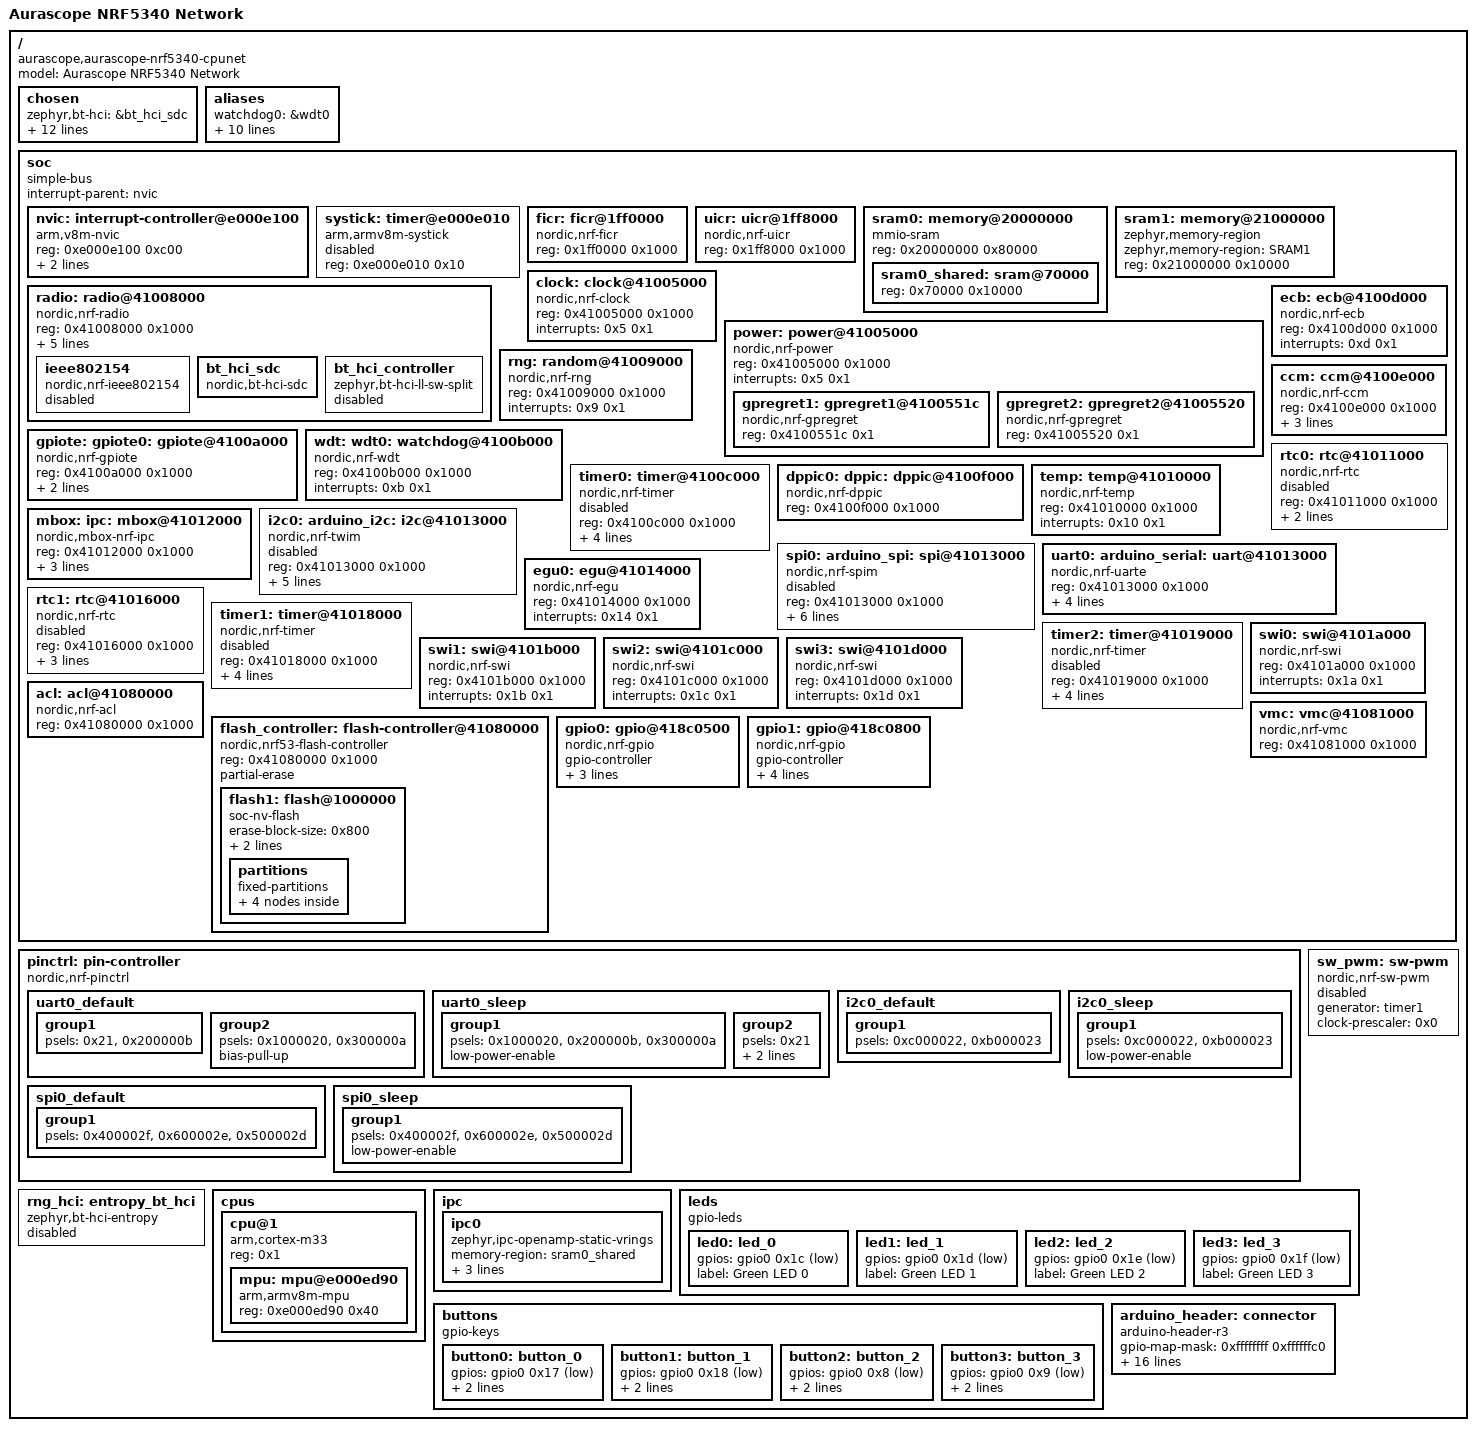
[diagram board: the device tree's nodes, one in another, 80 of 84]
/dts-v1/;

/* node '/' defined in zephyr/dts/common/skeleton.dtsi:9 */
/ {
	#address-cells = < 0x1 >;                          /* in zephyr/dts/common/skeleton.dtsi:10 */
	#size-cells = < 0x1 >;                             /* in zephyr/dts/common/skeleton.dtsi:11 */
	model = "Aurascope NRF5340 Network";               /* in nrf/boards/aurascope/aurascope/aurascope_nrf5340_cpunet.dts:12 */
	compatible = "aurascope,aurascope-nrf5340-cpunet"; /* in nrf/boards/aurascope/aurascope/aurascope_nrf5340_cpunet.dts:13 */

	/* node '/chosen' defined in zephyr/dts/common/skeleton.dtsi:13 */
	chosen {
		zephyr,bt-hci = &bt_hci_sdc;                 /* in zephyr/dts/arm/nordic/nrf5340_cpunet.dtsi:12 */
		zephyr,entropy = &rng;                       /* in zephyr/dts/arm/nordic/nrf5340_cpunet.dtsi:13 */
		zephyr,flash-controller = &flash_controller; /* in zephyr/dts/arm/nordic/nrf5340_cpunet.dtsi:14 */
		zephyr,console = &uart0;                     /* in nrf/boards/aurascope/aurascope/aurascope_nrf5340_cpunet.dts:16 */
		zephyr,shell-uart = &uart0;                  /* in nrf/boards/aurascope/aurascope/aurascope_nrf5340_cpunet.dts:17 */
		zephyr,uart-mcumgr = &uart0;                 /* in nrf/boards/aurascope/aurascope/aurascope_nrf5340_cpunet.dts:18 */
		zephyr,bt-mon-uart = &uart0;                 /* in nrf/boards/aurascope/aurascope/aurascope_nrf5340_cpunet.dts:19 */
		zephyr,bt-c2h-uart = &uart0;                 /* in nrf/boards/aurascope/aurascope/aurascope_nrf5340_cpunet.dts:20 */
		zephyr,bt-hci-ipc = &ipc0;                   /* in nrf/boards/aurascope/aurascope/aurascope_nrf5340_cpunet.dts:21 */
		zephyr,sram = &sram1;                        /* in nrf/boards/aurascope/aurascope/aurascope_nrf5340_cpunet.dts:22 */
		zephyr,flash = &flash1;                      /* in nrf/boards/aurascope/aurascope/aurascope_nrf5340_cpunet.dts:23 */
		zephyr,code-partition = &slot0_partition;    /* in nrf/boards/aurascope/aurascope/aurascope_nrf5340_cpunet.dts:24 */
		zephyr,ipc_shm = &sram0_shared;              /* in zephyr/dts/vendor/nordic/nrf5340_shared_sram_partition.dtsi:22 */
	};

	/* node '/aliases' defined in zephyr/dts/common/skeleton.dtsi:15 */
	aliases {
		watchdog0 = &wdt0;          /* in nrf/boards/aurascope/aurascope/aurascope_nrf5340_cpunet.dts:29 */
		led0 = &led0;               /* in nrf/boards/aurascope/aurascope/aurascope_nrf5340_shared.dtsi:93 */
		led1 = &led1;               /* in nrf/boards/aurascope/aurascope/aurascope_nrf5340_shared.dtsi:94 */
		led2 = &led2;               /* in nrf/boards/aurascope/aurascope/aurascope_nrf5340_shared.dtsi:95 */
		led3 = &led3;               /* in nrf/boards/aurascope/aurascope/aurascope_nrf5340_shared.dtsi:96 */
		sw0 = &button0;             /* in nrf/boards/aurascope/aurascope/aurascope_nrf5340_shared.dtsi:97 */
		sw1 = &button1;             /* in nrf/boards/aurascope/aurascope/aurascope_nrf5340_shared.dtsi:98 */
		sw2 = &button2;             /* in nrf/boards/aurascope/aurascope/aurascope_nrf5340_shared.dtsi:99 */
		sw3 = &button3;             /* in nrf/boards/aurascope/aurascope/aurascope_nrf5340_shared.dtsi:100 */
		mcuboot-button0 = &button0; /* in nrf/boards/aurascope/aurascope/aurascope_nrf5340_shared.dtsi:101 */
		mcuboot-led0 = &led0;       /* in nrf/boards/aurascope/aurascope/aurascope_nrf5340_shared.dtsi:102 */
	};

	/* node '/soc' defined in zephyr/dts/arm/armv8-m.dtsi:6 */
	soc {
		#address-cells = < 0x1 >;     /* in zephyr/dts/arm/armv8-m.dtsi:7 */
		#size-cells = < 0x1 >;        /* in zephyr/dts/arm/armv8-m.dtsi:8 */
		interrupt-parent = < &nvic >; /* in zephyr/dts/arm/armv8-m.dtsi:10 */
		ranges;                       /* in zephyr/dts/arm/armv8-m.dtsi:11 */
		compatible = "simple-bus";    /* in zephyr/dts/arm/nordic/nrf5340_cpunet_qkaa.dtsi:27 */

		/* node '/soc/interrupt-controller@e000e100' defined in zephyr/dts/arm/armv8-m.dtsi:13 */
		nvic: interrupt-controller@e000e100 {
			#address-cells = < 0x1 >;            /* in zephyr/dts/arm/armv8-m.dtsi:14 */
			compatible = "arm,v8m-nvic";         /* in zephyr/dts/arm/armv8-m.dtsi:15 */
			reg = < 0xe000e100 0xc00 >;          /* in zephyr/dts/arm/armv8-m.dtsi:16 */
			interrupt-controller;                /* in zephyr/dts/arm/armv8-m.dtsi:17 */
			#interrupt-cells = < 0x2 >;          /* in zephyr/dts/arm/armv8-m.dtsi:18 */
			arm,num-irq-priority-bits = < 0x3 >; /* in zephyr/dts/arm/nordic/nrf5340_cpunet.dtsi:368 */
			phandle = < 0x1 >;                   /* in zephyr/dts/arm/armv8-m.dtsi:10 */
		};

		/* node '/soc/timer@e000e010' defined in zephyr/dts/arm/armv8-m.dtsi:21 */
		systick: timer@e000e010 {
			compatible = "arm,armv8m-systick"; /* in zephyr/dts/arm/armv8-m.dtsi:22 */
			reg = < 0xe000e010 0x10 >;         /* in zephyr/dts/arm/armv8-m.dtsi:23 */
			status = "disabled";               /* in zephyr/dts/arm/nordic/nrf5340_cpunet.dtsi:373 */
		};

		/* node '/soc/ficr@1ff0000' defined in zephyr/dts/arm/nordic/nrf5340_cpunet.dtsi:36 */
		ficr: ficr@1ff0000 {
			compatible = "nordic,nrf-ficr"; /* in zephyr/dts/arm/nordic/nrf5340_cpunet.dtsi:37 */
			reg = < 0x1ff0000 0x1000 >;     /* in zephyr/dts/arm/nordic/nrf5340_cpunet.dtsi:38 */
			#nordic,ficr-cells = < 0x1 >;   /* in zephyr/dts/arm/nordic/nrf5340_cpunet.dtsi:39 */
			status = "okay";                /* in zephyr/dts/arm/nordic/nrf5340_cpunet.dtsi:40 */
		};

		/* node '/soc/uicr@1ff8000' defined in zephyr/dts/arm/nordic/nrf5340_cpunet.dtsi:43 */
		uicr: uicr@1ff8000 {
			compatible = "nordic,nrf-uicr"; /* in zephyr/dts/arm/nordic/nrf5340_cpunet.dtsi:44 */
			reg = < 0x1ff8000 0x1000 >;     /* in zephyr/dts/arm/nordic/nrf5340_cpunet.dtsi:45 */
			status = "okay";                /* in zephyr/dts/arm/nordic/nrf5340_cpunet.dtsi:46 */
		};

		/* node '/soc/memory@20000000' defined in zephyr/dts/arm/nordic/nrf5340_cpunet.dtsi:49 */
		sram0: memory@20000000 {
			compatible = "mmio-sram";            /* in zephyr/dts/arm/nordic/nrf5340_cpunet.dtsi:50 */
			#address-cells = < 0x1 >;            /* in zephyr/dts/arm/nordic/nrf5340_cpunet.dtsi:51 */
			#size-cells = < 0x1 >;               /* in zephyr/dts/arm/nordic/nrf5340_cpunet.dtsi:52 */
			reg = < 0x20000000 0x80000 >;        /* in zephyr/dts/arm/nordic/nrf5340_cpunet_qkaa.dtsi:16 */
			ranges = < 0x0 0x20000000 0x80000 >; /* in zephyr/dts/arm/nordic/nrf5340_cpunet_qkaa.dtsi:17 */

			/* node '/soc/memory@20000000/sram@70000' defined in zephyr/dts/vendor/nordic/nrf5340_shared_sram_partition.dtsi:27 */
			sram0_shared: sram@70000 {
				reg = < 0x70000 0x10000 >; /* in zephyr/dts/vendor/nordic/nrf5340_shared_sram_partition.dtsi:29 */
				phandle = < 0xb >;         /* in zephyr/dts/arm/nordic/nrf5340_cpunet.dtsi:358 */
			};
		};

		/* node '/soc/memory@21000000' defined in zephyr/dts/arm/nordic/nrf5340_cpunet.dtsi:55 */
		sram1: memory@21000000 {
			compatible = "zephyr,memory-region",
			             "mmio-sram";            /* in zephyr/dts/arm/nordic/nrf5340_cpunet.dtsi:56 */
			zephyr,memory-region = "SRAM1";      /* in zephyr/dts/arm/nordic/nrf5340_cpunet.dtsi:57 */
			#address-cells = < 0x1 >;            /* in zephyr/dts/arm/nordic/nrf5340_cpunet.dtsi:58 */
			#size-cells = < 0x1 >;               /* in zephyr/dts/arm/nordic/nrf5340_cpunet.dtsi:59 */
			reg = < 0x21000000 0x10000 >;        /* in zephyr/dts/arm/nordic/nrf5340_cpunet_qkaa.dtsi:21 */
			ranges = < 0x0 0x21000000 0x10000 >; /* in zephyr/dts/arm/nordic/nrf5340_cpunet_qkaa.dtsi:22 */
		};

		/* node '/soc/clock@41005000' defined in zephyr/dts/arm/nordic/nrf5340_cpunet.dtsi:62 */
		clock: clock@41005000 {
			compatible = "nordic,nrf-clock"; /* in zephyr/dts/arm/nordic/nrf5340_cpunet.dtsi:63 */
			reg = < 0x41005000 0x1000 >;     /* in zephyr/dts/arm/nordic/nrf5340_cpunet.dtsi:64 */
			interrupts = < 0x5 0x1 >;        /* in zephyr/dts/arm/nordic/nrf5340_cpunet.dtsi:65 */
			status = "okay";                 /* in zephyr/dts/arm/nordic/nrf5340_cpunet.dtsi:66 */
		};

		/* node '/soc/power@41005000' defined in zephyr/dts/arm/nordic/nrf5340_cpunet.dtsi:69 */
		power: power@41005000 {
			compatible = "nordic,nrf-power"; /* in zephyr/dts/arm/nordic/nrf5340_cpunet.dtsi:70 */
			reg = < 0x41005000 0x1000 >;     /* in zephyr/dts/arm/nordic/nrf5340_cpunet.dtsi:71 */
			interrupts = < 0x5 0x1 >;        /* in zephyr/dts/arm/nordic/nrf5340_cpunet.dtsi:72 */
			status = "okay";                 /* in zephyr/dts/arm/nordic/nrf5340_cpunet.dtsi:73 */
			#address-cells = < 0x1 >;        /* in zephyr/dts/arm/nordic/nrf5340_cpunet.dtsi:74 */
			#size-cells = < 0x1 >;           /* in zephyr/dts/arm/nordic/nrf5340_cpunet.dtsi:75 */

			/* node '/soc/power@41005000/gpregret1@4100551c' defined in zephyr/dts/arm/nordic/nrf5340_cpunet.dtsi:77 */
			gpregret1: gpregret1@4100551c {
				#address-cells = < 0x1 >;           /* in zephyr/dts/arm/nordic/nrf5340_cpunet.dtsi:78 */
				#size-cells = < 0x1 >;              /* in zephyr/dts/arm/nordic/nrf5340_cpunet.dtsi:79 */
				compatible = "nordic,nrf-gpregret"; /* in zephyr/dts/arm/nordic/nrf5340_cpunet.dtsi:80 */
				reg = < 0x4100551c 0x1 >;           /* in zephyr/dts/arm/nordic/nrf5340_cpunet.dtsi:81 */
				status = "okay";                    /* in zephyr/dts/arm/nordic/nrf5340_cpunet.dtsi:82 */
			};

			/* node '/soc/power@41005000/gpregret2@41005520' defined in zephyr/dts/arm/nordic/nrf5340_cpunet.dtsi:85 */
			gpregret2: gpregret2@41005520 {
				#address-cells = < 0x1 >;           /* in zephyr/dts/arm/nordic/nrf5340_cpunet.dtsi:86 */
				#size-cells = < 0x1 >;              /* in zephyr/dts/arm/nordic/nrf5340_cpunet.dtsi:87 */
				compatible = "nordic,nrf-gpregret"; /* in zephyr/dts/arm/nordic/nrf5340_cpunet.dtsi:88 */
				reg = < 0x41005520 0x1 >;           /* in zephyr/dts/arm/nordic/nrf5340_cpunet.dtsi:89 */
				status = "okay";                    /* in zephyr/dts/arm/nordic/nrf5340_cpunet.dtsi:90 */
			};
		};

		/* node '/soc/radio@41008000' defined in zephyr/dts/arm/nordic/nrf5340_cpunet.dtsi:94 */
		radio: radio@41008000 {
			compatible = "nordic,nrf-radio"; /* in zephyr/dts/arm/nordic/nrf5340_cpunet.dtsi:95 */
			reg = < 0x41008000 0x1000 >;     /* in zephyr/dts/arm/nordic/nrf5340_cpunet.dtsi:96 */
			interrupts = < 0x8 0x1 >;        /* in zephyr/dts/arm/nordic/nrf5340_cpunet.dtsi:97 */
			status = "okay";                 /* in zephyr/dts/arm/nordic/nrf5340_cpunet.dtsi:98 */
			dfe-supported;                   /* in zephyr/dts/arm/nordic/nrf5340_cpunet.dtsi:99 */
			ieee802154-supported;            /* in zephyr/dts/arm/nordic/nrf5340_cpunet.dtsi:100 */
			ble-2mbps-supported;             /* in zephyr/dts/arm/nordic/nrf5340_cpunet.dtsi:101 */
			ble-coded-phy-supported;         /* in zephyr/dts/arm/nordic/nrf5340_cpunet.dtsi:102 */

			/* node '/soc/radio@41008000/ieee802154' defined in zephyr/dts/arm/nordic/nrf5340_cpunet.dtsi:104 */
			ieee802154: ieee802154 {
				compatible = "nordic,nrf-ieee802154"; /* in zephyr/dts/arm/nordic/nrf5340_cpunet.dtsi:105 */
				status = "disabled";                  /* in zephyr/dts/arm/nordic/nrf5340_cpunet.dtsi:106 */
			};

			/* node '/soc/radio@41008000/bt_hci_sdc' defined in zephyr/dts/arm/nordic/nrf5340_cpunet.dtsi:109 */
			bt_hci_sdc: bt_hci_sdc {
				compatible = "nordic,bt-hci-sdc"; /* in zephyr/dts/arm/nordic/nrf5340_cpunet.dtsi:110 */
				status = "okay";                  /* in zephyr/dts/arm/nordic/nrf5340_cpunet.dtsi:111 */
			};

			/* node '/soc/radio@41008000/bt_hci_controller' defined in zephyr/dts/arm/nordic/nrf5340_cpunet.dtsi:113 */
			bt_hci_controller: bt_hci_controller {
				compatible = "zephyr,bt-hci-ll-sw-split"; /* in zephyr/dts/arm/nordic/nrf5340_cpunet.dtsi:114 */
				status = "disabled";                      /* in zephyr/dts/arm/nordic/nrf5340_cpunet.dtsi:115 */
			};
		};

		/* node '/soc/random@41009000' defined in zephyr/dts/arm/nordic/nrf5340_cpunet.dtsi:119 */
		rng: random@41009000 {
			compatible = "nordic,nrf-rng"; /* in zephyr/dts/arm/nordic/nrf5340_cpunet.dtsi:120 */
			reg = < 0x41009000 0x1000 >;   /* in zephyr/dts/arm/nordic/nrf5340_cpunet.dtsi:121 */
			interrupts = < 0x9 0x1 >;      /* in zephyr/dts/arm/nordic/nrf5340_cpunet.dtsi:122 */
			status = "okay";               /* in zephyr/dts/arm/nordic/nrf5340_cpunet.dtsi:123 */
		};

		/* node '/soc/gpiote@4100a000' defined in zephyr/dts/arm/nordic/nrf5340_cpunet.dtsi:126 */
		gpiote: gpiote0: gpiote@4100a000 {
			compatible = "nordic,nrf-gpiote"; /* in zephyr/dts/arm/nordic/nrf5340_cpunet.dtsi:127 */
			reg = < 0x4100a000 0x1000 >;      /* in zephyr/dts/arm/nordic/nrf5340_cpunet.dtsi:128 */
			interrupts = < 0xa 0x5 >;         /* in zephyr/dts/arm/nordic/nrf5340_cpunet.dtsi:129 */
			instance = < 0x0 >;               /* in zephyr/dts/arm/nordic/nrf5340_cpunet.dtsi:131 */
			status = "okay";                  /* in nrf/boards/aurascope/aurascope/aurascope_nrf5340_cpunet.dts:55 */
			phandle = < 0x9 >;                /* in zephyr/dts/arm/nordic/nrf5340_cpunet.dtsi:339 */
		};

		/* node '/soc/watchdog@4100b000' defined in zephyr/dts/arm/nordic/nrf5340_cpunet.dtsi:134 */
		wdt: wdt0: watchdog@4100b000 {
			compatible = "nordic,nrf-wdt"; /* in zephyr/dts/arm/nordic/nrf5340_cpunet.dtsi:135 */
			reg = < 0x4100b000 0x1000 >;   /* in zephyr/dts/arm/nordic/nrf5340_cpunet.dtsi:136 */
			interrupts = < 0xb 0x1 >;      /* in zephyr/dts/arm/nordic/nrf5340_cpunet.dtsi:137 */
			status = "okay";               /* in zephyr/dts/arm/nordic/nrf5340_cpunet.dtsi:138 */
		};

		/* node '/soc/timer@4100c000' defined in zephyr/dts/arm/nordic/nrf5340_cpunet.dtsi:141 */
		timer0: timer@4100c000 {
			compatible = "nordic,nrf-timer"; /* in zephyr/dts/arm/nordic/nrf5340_cpunet.dtsi:142 */
			status = "disabled";             /* in zephyr/dts/arm/nordic/nrf5340_cpunet.dtsi:143 */
			reg = < 0x4100c000 0x1000 >;     /* in zephyr/dts/arm/nordic/nrf5340_cpunet.dtsi:144 */
			cc-num = < 0x8 >;                /* in zephyr/dts/arm/nordic/nrf5340_cpunet.dtsi:145 */
			max-bit-width = < 0x20 >;        /* in zephyr/dts/arm/nordic/nrf5340_cpunet.dtsi:146 */
			interrupts = < 0xc 0x1 >;        /* in zephyr/dts/arm/nordic/nrf5340_cpunet.dtsi:147 */
			prescaler = < 0x0 >;             /* in zephyr/dts/arm/nordic/nrf5340_cpunet.dtsi:148 */
		};

		/* node '/soc/ecb@4100d000' defined in zephyr/dts/arm/nordic/nrf5340_cpunet.dtsi:151 */
		ecb: ecb@4100d000 {
			compatible = "nordic,nrf-ecb"; /* in zephyr/dts/arm/nordic/nrf5340_cpunet.dtsi:152 */
			reg = < 0x4100d000 0x1000 >;   /* in zephyr/dts/arm/nordic/nrf5340_cpunet.dtsi:153 */
			interrupts = < 0xd 0x1 >;      /* in zephyr/dts/arm/nordic/nrf5340_cpunet.dtsi:154 */
			status = "okay";               /* in zephyr/dts/arm/nordic/nrf5340_cpunet.dtsi:155 */
		};

		/* node '/soc/ccm@4100e000' defined in zephyr/dts/arm/nordic/nrf5340_cpunet.dtsi:158 */
		ccm: ccm@4100e000 {
			compatible = "nordic,nrf-ccm"; /* in zephyr/dts/arm/nordic/nrf5340_cpunet.dtsi:159 */
			reg = < 0x4100e000 0x1000 >;   /* in zephyr/dts/arm/nordic/nrf5340_cpunet.dtsi:160 */
			interrupts = < 0xe 0x1 >;      /* in zephyr/dts/arm/nordic/nrf5340_cpunet.dtsi:161 */
			length-field-length-8-bits;    /* in zephyr/dts/arm/nordic/nrf5340_cpunet.dtsi:162 */
			headermask-supported;          /* in zephyr/dts/arm/nordic/nrf5340_cpunet.dtsi:163 */
			status = "okay";               /* in zephyr/dts/arm/nordic/nrf5340_cpunet.dtsi:164 */
		};

		/* node '/soc/dppic@4100f000' defined in zephyr/dts/arm/nordic/nrf5340_cpunet.dtsi:167 */
		dppic0: dppic: dppic@4100f000 {
			compatible = "nordic,nrf-dppic"; /* in zephyr/dts/arm/nordic/nrf5340_cpunet.dtsi:168 */
			reg = < 0x4100f000 0x1000 >;     /* in zephyr/dts/arm/nordic/nrf5340_cpunet.dtsi:169 */
			status = "okay";                 /* in zephyr/dts/arm/nordic/nrf5340_cpunet.dtsi:170 */
		};

		/* node '/soc/temp@41010000' defined in zephyr/dts/arm/nordic/nrf5340_cpunet.dtsi:173 */
		temp: temp@41010000 {
			compatible = "nordic,nrf-temp"; /* in zephyr/dts/arm/nordic/nrf5340_cpunet.dtsi:174 */
			reg = < 0x41010000 0x1000 >;    /* in zephyr/dts/arm/nordic/nrf5340_cpunet.dtsi:175 */
			interrupts = < 0x10 0x1 >;      /* in zephyr/dts/arm/nordic/nrf5340_cpunet.dtsi:176 */
			status = "okay";                /* in zephyr/dts/arm/nordic/nrf5340_cpunet.dtsi:177 */
		};

		/* node '/soc/rtc@41011000' defined in zephyr/dts/arm/nordic/nrf5340_cpunet.dtsi:180 */
		rtc0: rtc@41011000 {
			compatible = "nordic,nrf-rtc"; /* in zephyr/dts/arm/nordic/nrf5340_cpunet.dtsi:181 */
			reg = < 0x41011000 0x1000 >;   /* in zephyr/dts/arm/nordic/nrf5340_cpunet.dtsi:182 */
			cc-num = < 0x4 >;              /* in zephyr/dts/arm/nordic/nrf5340_cpunet.dtsi:183 */
			interrupts = < 0x11 0x1 >;     /* in zephyr/dts/arm/nordic/nrf5340_cpunet.dtsi:184 */
			status = "disabled";           /* in zephyr/dts/arm/nordic/nrf5340_cpunet.dtsi:185 */
		};

		/* node '/soc/mbox@41012000' defined in zephyr/dts/arm/nordic/nrf5340_cpunet.dtsi:188 */
		mbox: ipc: mbox@41012000 {
			compatible = "nordic,mbox-nrf-ipc",
			             "nordic,nrf-ipc";      /* in zephyr/dts/arm/nordic/nrf5340_cpunet.dtsi:189 */
			reg = < 0x41012000 0x1000 >;        /* in zephyr/dts/arm/nordic/nrf5340_cpunet.dtsi:190 */
			tx-mask = < 0xffff >;               /* in zephyr/dts/arm/nordic/nrf5340_cpunet.dtsi:191 */
			rx-mask = < 0xffff >;               /* in zephyr/dts/arm/nordic/nrf5340_cpunet.dtsi:192 */
			interrupts = < 0x12 0x1 >;          /* in zephyr/dts/arm/nordic/nrf5340_cpunet.dtsi:193 */
			#mbox-cells = < 0x1 >;              /* in zephyr/dts/arm/nordic/nrf5340_cpunet.dtsi:194 */
			status = "okay";                    /* in zephyr/dts/arm/nordic/nrf5340_cpunet.dtsi:195 */
			phandle = < 0xc >;                  /* in zephyr/dts/arm/nordic/nrf5340_cpunet.dtsi:359 */
		};

		/* node '/soc/i2c@41013000' defined in zephyr/dts/arm/nordic/nrf5340_cpunet.dtsi:198 */
		i2c0: arduino_i2c: i2c@41013000 {
			#address-cells = < 0x1 >;       /* in zephyr/dts/arm/nordic/nrf5340_cpunet.dtsi:206 */
			#size-cells = < 0x0 >;          /* in zephyr/dts/arm/nordic/nrf5340_cpunet.dtsi:207 */
			reg = < 0x41013000 0x1000 >;    /* in zephyr/dts/arm/nordic/nrf5340_cpunet.dtsi:208 */
			interrupts = < 0x13 0x1 >;      /* in zephyr/dts/arm/nordic/nrf5340_cpunet.dtsi:209 */
			easydma-maxcnt-bits = < 0x10 >; /* in zephyr/dts/arm/nordic/nrf5340_cpunet.dtsi:210 */
			status = "disabled";            /* in zephyr/dts/arm/nordic/nrf5340_cpunet.dtsi:211 */
			zephyr,pm-device-runtime-auto;  /* in zephyr/dts/arm/nordic/nrf5340_cpunet.dtsi:212 */
			compatible = "nordic,nrf-twim"; /* in nrf/boards/aurascope/aurascope/aurascope_nrf5340_cpunet.dts:36 */
			pinctrl-0 = < &i2c0_default >;  /* in nrf/boards/aurascope/aurascope/aurascope_nrf5340_cpunet.dts:39 */
			pinctrl-1 = < &i2c0_sleep >;    /* in nrf/boards/aurascope/aurascope/aurascope_nrf5340_cpunet.dts:40 */
			pinctrl-names = "default",
			                "sleep";        /* in nrf/boards/aurascope/aurascope/aurascope_nrf5340_cpunet.dts:41 */
		};

		/* node '/soc/spi@41013000' defined in zephyr/dts/arm/nordic/nrf5340_cpunet.dtsi:215 */
		spi0: arduino_spi: spi@41013000 {
			#address-cells = < 0x1 >;                /* in zephyr/dts/arm/nordic/nrf5340_cpunet.dtsi:223 */
			#size-cells = < 0x0 >;                   /* in zephyr/dts/arm/nordic/nrf5340_cpunet.dtsi:224 */
			reg = < 0x41013000 0x1000 >;             /* in zephyr/dts/arm/nordic/nrf5340_cpunet.dtsi:225 */
			interrupts = < 0x13 0x1 >;               /* in zephyr/dts/arm/nordic/nrf5340_cpunet.dtsi:226 */
			max-frequency = < 0x7a1200 >;            /* in zephyr/dts/arm/nordic/nrf5340_cpunet.dtsi:227 */
			easydma-maxcnt-bits = < 0x10 >;          /* in zephyr/dts/arm/nordic/nrf5340_cpunet.dtsi:228 */
			status = "disabled";                     /* in zephyr/dts/arm/nordic/nrf5340_cpunet.dtsi:229 */
			compatible = "nordic,nrf-spim";          /* in nrf/boards/aurascope/aurascope/aurascope_nrf5340_cpunet.dts:45 */
			cs-gpios = < &arduino_header 0x10 0x1 >; /* in nrf/boards/aurascope/aurascope/aurascope_nrf5340_cpunet.dts:48 */
			pinctrl-0 = < &spi0_default >;           /* in nrf/boards/aurascope/aurascope/aurascope_nrf5340_cpunet.dts:49 */
			pinctrl-1 = < &spi0_sleep >;             /* in nrf/boards/aurascope/aurascope/aurascope_nrf5340_cpunet.dts:50 */
			pinctrl-names = "default",
			                "sleep";                 /* in nrf/boards/aurascope/aurascope/aurascope_nrf5340_cpunet.dts:51 */
		};

		/* node '/soc/uart@41013000' defined in zephyr/dts/arm/nordic/nrf5340_cpunet.dtsi:232 */
		uart0: arduino_serial: uart@41013000 {
			compatible = "nordic,nrf-uarte"; /* in zephyr/dts/arm/nordic/nrf5340_cpunet.dtsi:233 */
			reg = < 0x41013000 0x1000 >;     /* in zephyr/dts/arm/nordic/nrf5340_cpunet.dtsi:234 */
			interrupts = < 0x13 0x1 >;       /* in zephyr/dts/arm/nordic/nrf5340_cpunet.dtsi:235 */
			status = "okay";                 /* in nrf/boards/aurascope/aurascope/aurascope_nrf5340_cpunet.dts:67 */
			current-speed = < 0x1c200 >;     /* in nrf/boards/aurascope/aurascope/aurascope_nrf5340_cpunet.dts:68 */
			pinctrl-0 = < &uart0_default >;  /* in nrf/boards/aurascope/aurascope/aurascope_nrf5340_cpunet.dts:69 */
			pinctrl-1 = < &uart0_sleep >;    /* in nrf/boards/aurascope/aurascope/aurascope_nrf5340_cpunet.dts:70 */
			pinctrl-names = "default",
			                "sleep";         /* in nrf/boards/aurascope/aurascope/aurascope_nrf5340_cpunet.dts:71 */
		};

		/* node '/soc/egu@41014000' defined in zephyr/dts/arm/nordic/nrf5340_cpunet.dtsi:239 */
		egu0: egu@41014000 {
			compatible = "nordic,nrf-egu"; /* in zephyr/dts/arm/nordic/nrf5340_cpunet.dtsi:240 */
			reg = < 0x41014000 0x1000 >;   /* in zephyr/dts/arm/nordic/nrf5340_cpunet.dtsi:241 */
			interrupts = < 0x14 0x1 >;     /* in zephyr/dts/arm/nordic/nrf5340_cpunet.dtsi:242 */
			status = "okay";               /* in zephyr/dts/arm/nordic/nrf5340_cpunet.dtsi:243 */
		};

		/* node '/soc/rtc@41016000' defined in zephyr/dts/arm/nordic/nrf5340_cpunet.dtsi:246 */
		rtc1: rtc@41016000 {
			compatible = "nordic,nrf-rtc"; /* in zephyr/dts/arm/nordic/nrf5340_cpunet.dtsi:247 */
			reg = < 0x41016000 0x1000 >;   /* in zephyr/dts/arm/nordic/nrf5340_cpunet.dtsi:248 */
			cc-num = < 0x4 >;              /* in zephyr/dts/arm/nordic/nrf5340_cpunet.dtsi:249 */
			interrupts = < 0x16 0x1 >;     /* in zephyr/dts/arm/nordic/nrf5340_cpunet.dtsi:250 */
			clock-frequency = < 0x8000 >;  /* in zephyr/dts/arm/nordic/nrf5340_cpunet.dtsi:251 */
			status = "disabled";           /* in zephyr/dts/arm/nordic/nrf5340_cpunet.dtsi:252 */
		};

		/* node '/soc/timer@41018000' defined in zephyr/dts/arm/nordic/nrf5340_cpunet.dtsi:255 */
		timer1: timer@41018000 {
			compatible = "nordic,nrf-timer"; /* in zephyr/dts/arm/nordic/nrf5340_cpunet.dtsi:256 */
			status = "disabled";             /* in zephyr/dts/arm/nordic/nrf5340_cpunet.dtsi:257 */
			reg = < 0x41018000 0x1000 >;     /* in zephyr/dts/arm/nordic/nrf5340_cpunet.dtsi:258 */
			cc-num = < 0x8 >;                /* in zephyr/dts/arm/nordic/nrf5340_cpunet.dtsi:259 */
			max-bit-width = < 0x20 >;        /* in zephyr/dts/arm/nordic/nrf5340_cpunet.dtsi:260 */
			interrupts = < 0x18 0x1 >;       /* in zephyr/dts/arm/nordic/nrf5340_cpunet.dtsi:261 */
			prescaler = < 0x0 >;             /* in zephyr/dts/arm/nordic/nrf5340_cpunet.dtsi:262 */
			phandle = < 0xa >;               /* in zephyr/dts/vendor/nordic/nrf_common.dtsi:42 */
		};

		/* node '/soc/timer@41019000' defined in zephyr/dts/arm/nordic/nrf5340_cpunet.dtsi:265 */
		timer2: timer@41019000 {
			compatible = "nordic,nrf-timer"; /* in zephyr/dts/arm/nordic/nrf5340_cpunet.dtsi:266 */
			status = "disabled";             /* in zephyr/dts/arm/nordic/nrf5340_cpunet.dtsi:267 */
			reg = < 0x41019000 0x1000 >;     /* in zephyr/dts/arm/nordic/nrf5340_cpunet.dtsi:268 */
			cc-num = < 0x8 >;                /* in zephyr/dts/arm/nordic/nrf5340_cpunet.dtsi:269 */
			max-bit-width = < 0x20 >;        /* in zephyr/dts/arm/nordic/nrf5340_cpunet.dtsi:270 */
			interrupts = < 0x19 0x1 >;       /* in zephyr/dts/arm/nordic/nrf5340_cpunet.dtsi:271 */
			prescaler = < 0x0 >;             /* in zephyr/dts/arm/nordic/nrf5340_cpunet.dtsi:272 */
		};

		/* node '/soc/swi@4101a000' defined in zephyr/dts/arm/nordic/nrf5340_cpunet.dtsi:275 */
		swi0: swi@4101a000 {
			compatible = "nordic,nrf-swi"; /* in zephyr/dts/arm/nordic/nrf5340_cpunet.dtsi:276 */
			reg = < 0x4101a000 0x1000 >;   /* in zephyr/dts/arm/nordic/nrf5340_cpunet.dtsi:277 */
			interrupts = < 0x1a 0x1 >;     /* in zephyr/dts/arm/nordic/nrf5340_cpunet.dtsi:278 */
			status = "okay";               /* in zephyr/dts/arm/nordic/nrf5340_cpunet.dtsi:279 */
		};

		/* node '/soc/swi@4101b000' defined in zephyr/dts/arm/nordic/nrf5340_cpunet.dtsi:282 */
		swi1: swi@4101b000 {
			compatible = "nordic,nrf-swi"; /* in zephyr/dts/arm/nordic/nrf5340_cpunet.dtsi:283 */
			reg = < 0x4101b000 0x1000 >;   /* in zephyr/dts/arm/nordic/nrf5340_cpunet.dtsi:284 */
			interrupts = < 0x1b 0x1 >;     /* in zephyr/dts/arm/nordic/nrf5340_cpunet.dtsi:285 */
			status = "okay";               /* in zephyr/dts/arm/nordic/nrf5340_cpunet.dtsi:286 */
		};

		/* node '/soc/swi@4101c000' defined in zephyr/dts/arm/nordic/nrf5340_cpunet.dtsi:289 */
		swi2: swi@4101c000 {
			compatible = "nordic,nrf-swi"; /* in zephyr/dts/arm/nordic/nrf5340_cpunet.dtsi:290 */
			reg = < 0x4101c000 0x1000 >;   /* in zephyr/dts/arm/nordic/nrf5340_cpunet.dtsi:291 */
			interrupts = < 0x1c 0x1 >;     /* in zephyr/dts/arm/nordic/nrf5340_cpunet.dtsi:292 */
			status = "okay";               /* in zephyr/dts/arm/nordic/nrf5340_cpunet.dtsi:293 */
		};

		/* node '/soc/swi@4101d000' defined in zephyr/dts/arm/nordic/nrf5340_cpunet.dtsi:296 */
		swi3: swi@4101d000 {
			compatible = "nordic,nrf-swi"; /* in zephyr/dts/arm/nordic/nrf5340_cpunet.dtsi:297 */
			reg = < 0x4101d000 0x1000 >;   /* in zephyr/dts/arm/nordic/nrf5340_cpunet.dtsi:298 */
			interrupts = < 0x1d 0x1 >;     /* in zephyr/dts/arm/nordic/nrf5340_cpunet.dtsi:299 */
			status = "okay";               /* in zephyr/dts/arm/nordic/nrf5340_cpunet.dtsi:300 */
		};

		/* node '/soc/acl@41080000' defined in zephyr/dts/arm/nordic/nrf5340_cpunet.dtsi:303 */
		acl: acl@41080000 {
			compatible = "nordic,nrf-acl"; /* in zephyr/dts/arm/nordic/nrf5340_cpunet.dtsi:304 */
			reg = < 0x41080000 0x1000 >;   /* in zephyr/dts/arm/nordic/nrf5340_cpunet.dtsi:305 */
			status = "okay";               /* in zephyr/dts/arm/nordic/nrf5340_cpunet.dtsi:306 */
		};

		/* node '/soc/flash-controller@41080000' defined in zephyr/dts/arm/nordic/nrf5340_cpunet.dtsi:309 */
		flash_controller: flash-controller@41080000 {
			compatible = "nordic,nrf53-flash-controller"; /* in zephyr/dts/arm/nordic/nrf5340_cpunet.dtsi:310 */
			reg = < 0x41080000 0x1000 >;                  /* in zephyr/dts/arm/nordic/nrf5340_cpunet.dtsi:311 */
			partial-erase;                                /* in zephyr/dts/arm/nordic/nrf5340_cpunet.dtsi:312 */
			#address-cells = < 0x1 >;                     /* in zephyr/dts/arm/nordic/nrf5340_cpunet.dtsi:314 */
			#size-cells = < 0x1 >;                        /* in zephyr/dts/arm/nordic/nrf5340_cpunet.dtsi:315 */

			/* node '/soc/flash-controller@41080000/flash@1000000' defined in zephyr/dts/arm/nordic/nrf5340_cpunet.dtsi:317 */
			flash1: flash@1000000 {
				compatible = "soc-nv-flash";        /* in zephyr/dts/arm/nordic/nrf5340_cpunet.dtsi:318 */
				erase-block-size = < 0x800 >;       /* in zephyr/dts/arm/nordic/nrf5340_cpunet.dtsi:319 */
				write-block-size = < 0x4 >;         /* in zephyr/dts/arm/nordic/nrf5340_cpunet.dtsi:320 */
				#address-cells = < 0x1 >;           /* in zephyr/dts/arm/nordic/nrf5340_cpunet.dtsi:321 */
				#size-cells = < 0x1 >;              /* in zephyr/dts/arm/nordic/nrf5340_cpunet.dtsi:322 */
				reg = < 0x1000000 0x40000 >;        /* in zephyr/dts/arm/nordic/nrf5340_cpunet_qkaa.dtsi:11 */
				ranges = < 0x0 0x1000000 0x40000 >; /* in zephyr/dts/arm/nordic/nrf5340_cpunet_qkaa.dtsi:12 */

				/* node '/soc/flash-controller@41080000/flash@1000000/partitions' defined in nrf/boards/aurascope/aurascope/aurascope_nrf5340_cpunet.dts:75 */
				partitions {
					compatible = "fixed-partitions"; /* in nrf/boards/aurascope/aurascope/aurascope_nrf5340_cpunet.dts:76 */
					#address-cells = < 0x1 >;        /* in nrf/boards/aurascope/aurascope/aurascope_nrf5340_cpunet.dts:77 */
					#size-cells = < 0x1 >;           /* in nrf/boards/aurascope/aurascope/aurascope_nrf5340_cpunet.dts:78 */
					ranges;                          /* in nrf/boards/aurascope/aurascope/aurascope_nrf5340_cpunet.dts:79 */

					/* node '/soc/flash-controller@41080000/flash@1000000/partitions/partition@0' defined in nrf/boards/aurascope/aurascope/aurascope_nrf5340_cpunet.dts:81 */
					boot_partition: partition@0 {
						label = "mcuboot";    /* in nrf/boards/aurascope/aurascope/aurascope_nrf5340_cpunet.dts:82 */
						reg = < 0x0 0xc000 >; /* in nrf/boards/aurascope/aurascope/aurascope_nrf5340_cpunet.dts:83 */
					};

					/* node '/soc/flash-controller@41080000/flash@1000000/partitions/partition@c000' defined in nrf/boards/aurascope/aurascope/aurascope_nrf5340_cpunet.dts:86 */
					slot0_partition: partition@c000 {
						label = "image-0";        /* in nrf/boards/aurascope/aurascope/aurascope_nrf5340_cpunet.dts:87 */
						reg = < 0xc000 0x12000 >; /* in nrf/boards/aurascope/aurascope/aurascope_nrf5340_cpunet.dts:88 */
					};

					/* node '/soc/flash-controller@41080000/flash@1000000/partitions/partition@1e000' defined in nrf/boards/aurascope/aurascope/aurascope_nrf5340_cpunet.dts:91 */
					slot1_partition: partition@1e000 {
						label = "image-1";         /* in nrf/boards/aurascope/aurascope/aurascope_nrf5340_cpunet.dts:92 */
						reg = < 0x1e000 0x12000 >; /* in nrf/boards/aurascope/aurascope/aurascope_nrf5340_cpunet.dts:93 */
					};

					/* node '/soc/flash-controller@41080000/flash@1000000/partitions/partition@3a000' defined in nrf/boards/aurascope/aurascope/aurascope_nrf5340_cpunet.dts:96 */
					storage_partition: partition@3a000 {
						label = "storage";        /* in nrf/boards/aurascope/aurascope/aurascope_nrf5340_cpunet.dts:97 */
						reg = < 0x3a000 0x6000 >; /* in nrf/boards/aurascope/aurascope/aurascope_nrf5340_cpunet.dts:98 */
					};
				};
			};
		};

		/* node '/soc/vmc@41081000' defined in zephyr/dts/arm/nordic/nrf5340_cpunet.dtsi:326 */
		vmc: vmc@41081000 {
			compatible = "nordic,nrf-vmc"; /* in zephyr/dts/arm/nordic/nrf5340_cpunet.dtsi:327 */
			reg = < 0x41081000 0x1000 >;   /* in zephyr/dts/arm/nordic/nrf5340_cpunet.dtsi:328 */
			status = "okay";               /* in zephyr/dts/arm/nordic/nrf5340_cpunet.dtsi:329 */
		};

		/* node '/soc/gpio@418c0500' defined in zephyr/dts/arm/nordic/nrf5340_cpunet.dtsi:332 */
		gpio0: gpio@418c0500 {
			compatible = "nordic,nrf-gpio"; /* in zephyr/dts/arm/nordic/nrf5340_cpunet.dtsi:333 */
			gpio-controller;                /* in zephyr/dts/arm/nordic/nrf5340_cpunet.dtsi:334 */
			reg = < 0x418c0500 0x300 >;     /* in zephyr/dts/arm/nordic/nrf5340_cpunet.dtsi:335 */
			#gpio-cells = < 0x2 >;          /* in zephyr/dts/arm/nordic/nrf5340_cpunet.dtsi:336 */
			port = < 0x0 >;                 /* in zephyr/dts/arm/nordic/nrf5340_cpunet.dtsi:338 */
			gpiote-instance = < &gpiote >;  /* in zephyr/dts/arm/nordic/nrf5340_cpunet.dtsi:339 */
			status = "okay";                /* in nrf/boards/aurascope/aurascope/aurascope_nrf5340_cpunet.dts:59 */
			phandle = < 0xd >;              /* in nrf/boards/aurascope/aurascope/aurascope_nrf5340_shared.dtsi:14 */
		};

		/* node '/soc/gpio@418c0800' defined in zephyr/dts/arm/nordic/nrf5340_cpunet.dtsi:342 */
		gpio1: gpio@418c0800 {
			compatible = "nordic,nrf-gpio"; /* in zephyr/dts/arm/nordic/nrf5340_cpunet.dtsi:343 */
			gpio-controller;                /* in zephyr/dts/arm/nordic/nrf5340_cpunet.dtsi:344 */
			reg = < 0x418c0800 0x300 >;     /* in zephyr/dts/arm/nordic/nrf5340_cpunet.dtsi:345 */
			#gpio-cells = < 0x2 >;          /* in zephyr/dts/arm/nordic/nrf5340_cpunet.dtsi:346 */
			ngpios = < 0x10 >;              /* in zephyr/dts/arm/nordic/nrf5340_cpunet.dtsi:347 */
			port = < 0x1 >;                 /* in zephyr/dts/arm/nordic/nrf5340_cpunet.dtsi:349 */
			gpiote-instance = < &gpiote >;  /* in zephyr/dts/arm/nordic/nrf5340_cpunet.dtsi:350 */
			status = "okay";                /* in nrf/boards/aurascope/aurascope/aurascope_nrf5340_cpunet.dts:63 */
			phandle = < 0xe >;              /* in nrf/boards/aurascope/aurascope/aurascope_nrf5340_shared.dtsi:67 */
		};
	};

	/* node '/pin-controller' defined in zephyr/dts/vendor/nordic/nrf_common.dtsi:26 */
	pinctrl: pin-controller {
		compatible = "nordic,nrf-pinctrl"; /* in zephyr/dts/vendor/nordic/nrf_common.dtsi:31 */

		/* node '/pin-controller/uart0_default' defined in nrf/boards/aurascope/aurascope/aurascope_nrf5340_cpunet-pinctrl.dtsi:7 */
		uart0_default: uart0_default {
			phandle = < 0x7 >; /* in nrf/boards/aurascope/aurascope/aurascope_nrf5340_cpunet.dts:69 */

			/* node '/pin-controller/uart0_default/group1' defined in nrf/boards/aurascope/aurascope/aurascope_nrf5340_cpunet-pinctrl.dtsi:8 */
			group1 {
				psels = < 0x21 >,
				        < 0x200000b >; /* in nrf/boards/aurascope/aurascope/aurascope_nrf5340_cpunet-pinctrl.dtsi:9 */
			};

			/* node '/pin-controller/uart0_default/group2' defined in nrf/boards/aurascope/aurascope/aurascope_nrf5340_cpunet-pinctrl.dtsi:13 */
			group2 {
				psels = < 0x1000020 >,
				        < 0x300000a >; /* in nrf/boards/aurascope/aurascope/aurascope_nrf5340_cpunet-pinctrl.dtsi:14 */
				bias-pull-up;          /* in nrf/boards/aurascope/aurascope/aurascope_nrf5340_cpunet-pinctrl.dtsi:16 */
			};
		};

		/* node '/pin-controller/uart0_sleep' defined in nrf/boards/aurascope/aurascope/aurascope_nrf5340_cpunet-pinctrl.dtsi:20 */
		uart0_sleep: uart0_sleep {
			phandle = < 0x8 >; /* in nrf/boards/aurascope/aurascope/aurascope_nrf5340_cpunet.dts:70 */

			/* node '/pin-controller/uart0_sleep/group1' defined in nrf/boards/aurascope/aurascope/aurascope_nrf5340_cpunet-pinctrl.dtsi:21 */
			group1 {
				psels = < 0x1000020 >,
				        < 0x200000b >,
				        < 0x300000a >; /* in nrf/boards/aurascope/aurascope/aurascope_nrf5340_cpunet-pinctrl.dtsi:22 */
				low-power-enable;      /* in nrf/boards/aurascope/aurascope/aurascope_nrf5340_cpunet-pinctrl.dtsi:25 */
			};

			/* node '/pin-controller/uart0_sleep/group2' defined in nrf/boards/aurascope/aurascope/aurascope_nrf5340_cpunet-pinctrl.dtsi:28 */
			group2 {
				psels = < 0x21 >; /* in nrf/boards/aurascope/aurascope/aurascope_nrf5340_cpunet-pinctrl.dtsi:29 */
				low-power-enable; /* in nrf/boards/aurascope/aurascope/aurascope_nrf5340_cpunet-pinctrl.dtsi:30 */
				bias-pull-up;     /* in nrf/boards/aurascope/aurascope/aurascope_nrf5340_cpunet-pinctrl.dtsi:31 */
			};
		};

		/* node '/pin-controller/i2c0_default' defined in nrf/boards/aurascope/aurascope/aurascope_nrf5340_cpunet-pinctrl.dtsi:35 */
		i2c0_default: i2c0_default {
			phandle = < 0x2 >; /* in nrf/boards/aurascope/aurascope/aurascope_nrf5340_cpunet.dts:39 */

			/* node '/pin-controller/i2c0_default/group1' defined in nrf/boards/aurascope/aurascope/aurascope_nrf5340_cpunet-pinctrl.dtsi:36 */
			group1 {
				psels = < 0xc000022 >,
				        < 0xb000023 >; /* in nrf/boards/aurascope/aurascope/aurascope_nrf5340_cpunet-pinctrl.dtsi:37 */
			};
		};

		/* node '/pin-controller/i2c0_sleep' defined in nrf/boards/aurascope/aurascope/aurascope_nrf5340_cpunet-pinctrl.dtsi:42 */
		i2c0_sleep: i2c0_sleep {
			phandle = < 0x3 >; /* in nrf/boards/aurascope/aurascope/aurascope_nrf5340_cpunet.dts:40 */

			/* node '/pin-controller/i2c0_sleep/group1' defined in nrf/boards/aurascope/aurascope/aurascope_nrf5340_cpunet-pinctrl.dtsi:43 */
			group1 {
				psels = < 0xc000022 >,
				        < 0xb000023 >; /* in nrf/boards/aurascope/aurascope/aurascope_nrf5340_cpunet-pinctrl.dtsi:44 */
				low-power-enable;      /* in nrf/boards/aurascope/aurascope/aurascope_nrf5340_cpunet-pinctrl.dtsi:46 */
			};
		};

		/* node '/pin-controller/spi0_default' defined in nrf/boards/aurascope/aurascope/aurascope_nrf5340_cpunet-pinctrl.dtsi:50 */
		spi0_default: spi0_default {
			phandle = < 0x5 >; /* in nrf/boards/aurascope/aurascope/aurascope_nrf5340_cpunet.dts:49 */

			/* node '/pin-controller/spi0_default/group1' defined in nrf/boards/aurascope/aurascope/aurascope_nrf5340_cpunet-pinctrl.dtsi:51 */
			group1 {
				psels = < 0x400002f >,
				        < 0x600002e >,
				        < 0x500002d >; /* in nrf/boards/aurascope/aurascope/aurascope_nrf5340_cpunet-pinctrl.dtsi:52 */
			};
		};

		/* node '/pin-controller/spi0_sleep' defined in nrf/boards/aurascope/aurascope/aurascope_nrf5340_cpunet-pinctrl.dtsi:58 */
		spi0_sleep: spi0_sleep {
			phandle = < 0x6 >; /* in nrf/boards/aurascope/aurascope/aurascope_nrf5340_cpunet.dts:50 */

			/* node '/pin-controller/spi0_sleep/group1' defined in nrf/boards/aurascope/aurascope/aurascope_nrf5340_cpunet-pinctrl.dtsi:59 */
			group1 {
				psels = < 0x400002f >,
				        < 0x600002e >,
				        < 0x500002d >; /* in nrf/boards/aurascope/aurascope/aurascope_nrf5340_cpunet-pinctrl.dtsi:60 */
				low-power-enable;      /* in nrf/boards/aurascope/aurascope/aurascope_nrf5340_cpunet-pinctrl.dtsi:63 */
			};
		};
	};

	/* node '/entropy_bt_hci' defined in zephyr/dts/vendor/nordic/nrf_common.dtsi:34 */
	rng_hci: entropy_bt_hci {
		compatible = "zephyr,bt-hci-entropy"; /* in zephyr/dts/vendor/nordic/nrf_common.dtsi:35 */
		status = "disabled";                  /* in zephyr/dts/vendor/nordic/nrf_common.dtsi:36 */
	};

	/* node '/sw-pwm' defined in zephyr/dts/vendor/nordic/nrf_common.dtsi:39 */
	sw_pwm: sw-pwm {
		compatible = "nordic,nrf-sw-pwm"; /* in zephyr/dts/vendor/nordic/nrf_common.dtsi:40 */
		status = "disabled";              /* in zephyr/dts/vendor/nordic/nrf_common.dtsi:41 */
		generator = < &timer1 >;          /* in zephyr/dts/vendor/nordic/nrf_common.dtsi:42 */
		clock-prescaler = < 0x0 >;        /* in zephyr/dts/vendor/nordic/nrf_common.dtsi:43 */
		#pwm-cells = < 0x3 >;             /* in zephyr/dts/vendor/nordic/nrf_common.dtsi:44 */
	};

	/* node '/cpus' defined in zephyr/dts/arm/nordic/nrf5340_cpunet.dtsi:17 */
	cpus {
		#address-cells = < 0x1 >; /* in zephyr/dts/arm/nordic/nrf5340_cpunet.dtsi:18 */
		#size-cells = < 0x0 >;    /* in zephyr/dts/arm/nordic/nrf5340_cpunet.dtsi:19 */

		/* node '/cpus/cpu@1' defined in zephyr/dts/arm/nordic/nrf5340_cpunet.dtsi:21 */
		cpu@1 {
			device_type = "cpu";           /* in zephyr/dts/arm/nordic/nrf5340_cpunet.dtsi:22 */
			compatible = "arm,cortex-m33"; /* in zephyr/dts/arm/nordic/nrf5340_cpunet.dtsi:23 */
			reg = < 0x1 >;                 /* in zephyr/dts/arm/nordic/nrf5340_cpunet.dtsi:24 */
			#address-cells = < 0x1 >;      /* in zephyr/dts/arm/nordic/nrf5340_cpunet.dtsi:25 */
			#size-cells = < 0x1 >;         /* in zephyr/dts/arm/nordic/nrf5340_cpunet.dtsi:26 */

			/* node '/cpus/cpu@1/mpu@e000ed90' defined in zephyr/dts/arm/nordic/nrf5340_cpunet.dtsi:28 */
			mpu: mpu@e000ed90 {
				compatible = "arm,armv8m-mpu"; /* in zephyr/dts/arm/nordic/nrf5340_cpunet.dtsi:29 */
				reg = < 0xe000ed90 0x40 >;     /* in zephyr/dts/arm/nordic/nrf5340_cpunet.dtsi:30 */
			};
		};
	};

	/* node '/ipc' defined in zephyr/dts/arm/nordic/nrf5340_cpunet.dtsi:355 */
	ipc {

		/* node '/ipc/ipc0' defined in zephyr/dts/arm/nordic/nrf5340_cpunet.dtsi:356 */
		ipc0: ipc0 {
			compatible = "zephyr,ipc-openamp-static-vrings"; /* in zephyr/dts/arm/nordic/nrf5340_cpunet.dtsi:357 */
			memory-region = < &sram0_shared >;               /* in zephyr/dts/arm/nordic/nrf5340_cpunet.dtsi:358 */
			mboxes = < &mbox 0x0 >,
			         < &mbox 0x1 >;                          /* in zephyr/dts/arm/nordic/nrf5340_cpunet.dtsi:359 */
			mbox-names = "rx",
			             "tx";                               /* in zephyr/dts/arm/nordic/nrf5340_cpunet.dtsi:360 */
			role = "remote";                                 /* in zephyr/dts/arm/nordic/nrf5340_cpunet.dtsi:361 */
			status = "okay";                                 /* in zephyr/dts/arm/nordic/nrf5340_cpunet.dtsi:362 */
		};
	};

	/* node '/leds' defined in nrf/boards/aurascope/aurascope/aurascope_nrf5340_shared.dtsi:10 */
	leds {
		compatible = "gpio-leds"; /* in nrf/boards/aurascope/aurascope/aurascope_nrf5340_shared.dtsi:11 */

		/* node '/leds/led_0' defined in nrf/boards/aurascope/aurascope/aurascope_nrf5340_shared.dtsi:13 */
		led0: led_0 {
			gpios = < &gpio0 0x1c 0x1 >; /* in nrf/boards/aurascope/aurascope/aurascope_nrf5340_shared.dtsi:14 */
			label = "Green LED 0";       /* in nrf/boards/aurascope/aurascope/aurascope_nrf5340_shared.dtsi:15 */
		};

		/* node '/leds/led_1' defined in nrf/boards/aurascope/aurascope/aurascope_nrf5340_shared.dtsi:18 */
		led1: led_1 {
			gpios = < &gpio0 0x1d 0x1 >; /* in nrf/boards/aurascope/aurascope/aurascope_nrf5340_shared.dtsi:19 */
			label = "Green LED 1";       /* in nrf/boards/aurascope/aurascope/aurascope_nrf5340_shared.dtsi:20 */
		};

		/* node '/leds/led_2' defined in nrf/boards/aurascope/aurascope/aurascope_nrf5340_shared.dtsi:23 */
		led2: led_2 {
			gpios = < &gpio0 0x1e 0x1 >; /* in nrf/boards/aurascope/aurascope/aurascope_nrf5340_shared.dtsi:24 */
			label = "Green LED 2";       /* in nrf/boards/aurascope/aurascope/aurascope_nrf5340_shared.dtsi:25 */
		};

		/* node '/leds/led_3' defined in nrf/boards/aurascope/aurascope/aurascope_nrf5340_shared.dtsi:28 */
		led3: led_3 {
			gpios = < &gpio0 0x1f 0x1 >; /* in nrf/boards/aurascope/aurascope/aurascope_nrf5340_shared.dtsi:29 */
			label = "Green LED 3";       /* in nrf/boards/aurascope/aurascope/aurascope_nrf5340_shared.dtsi:30 */
		};
	};

	/* node '/buttons' defined in nrf/boards/aurascope/aurascope/aurascope_nrf5340_shared.dtsi:34 */
	buttons {
		compatible = "gpio-keys"; /* in nrf/boards/aurascope/aurascope/aurascope_nrf5340_shared.dtsi:35 */

		/* node '/buttons/button_0' defined in nrf/boards/aurascope/aurascope/aurascope_nrf5340_shared.dtsi:37 */
		button0: button_0 {
			gpios = < &gpio0 0x17 0x11 >; /* in nrf/boards/aurascope/aurascope/aurascope_nrf5340_shared.dtsi:38 */
			label = "Push button 1";      /* in nrf/boards/aurascope/aurascope/aurascope_nrf5340_shared.dtsi:39 */
			zephyr,code = < 0xb >;        /* in nrf/boards/aurascope/aurascope/aurascope_nrf5340_shared.dtsi:40 */
		};

		/* node '/buttons/button_1' defined in nrf/boards/aurascope/aurascope/aurascope_nrf5340_shared.dtsi:43 */
		button1: button_1 {
			gpios = < &gpio0 0x18 0x11 >; /* in nrf/boards/aurascope/aurascope/aurascope_nrf5340_shared.dtsi:44 */
			label = "Push button 2";      /* in nrf/boards/aurascope/aurascope/aurascope_nrf5340_shared.dtsi:45 */
			zephyr,code = < 0x2 >;        /* in nrf/boards/aurascope/aurascope/aurascope_nrf5340_shared.dtsi:46 */
		};

		/* node '/buttons/button_2' defined in nrf/boards/aurascope/aurascope/aurascope_nrf5340_shared.dtsi:49 */
		button2: button_2 {
			gpios = < &gpio0 0x8 0x11 >; /* in nrf/boards/aurascope/aurascope/aurascope_nrf5340_shared.dtsi:50 */
			label = "Push button 3";     /* in nrf/boards/aurascope/aurascope/aurascope_nrf5340_shared.dtsi:51 */
			zephyr,code = < 0x3 >;       /* in nrf/boards/aurascope/aurascope/aurascope_nrf5340_shared.dtsi:52 */
		};

		/* node '/buttons/button_3' defined in nrf/boards/aurascope/aurascope/aurascope_nrf5340_shared.dtsi:55 */
		button3: button_3 {
			gpios = < &gpio0 0x9 0x11 >; /* in nrf/boards/aurascope/aurascope/aurascope_nrf5340_shared.dtsi:56 */
			label = "Push button 4";     /* in nrf/boards/aurascope/aurascope/aurascope_nrf5340_shared.dtsi:57 */
			zephyr,code = < 0x4 >;       /* in nrf/boards/aurascope/aurascope/aurascope_nrf5340_shared.dtsi:58 */
		};
	};

	/* node '/connector' defined in nrf/boards/aurascope/aurascope/aurascope_nrf5340_shared.dtsi:62 */
	arduino_header: connector {
		compatible = "arduino-header-r3";          /* in nrf/boards/aurascope/aurascope/aurascope_nrf5340_shared.dtsi:63 */
		#gpio-cells = < 0x2 >;                     /* in nrf/boards/aurascope/aurascope/aurascope_nrf5340_shared.dtsi:64 */
		gpio-map-mask = < 0xffffffff 0xffffffc0 >; /* in nrf/boards/aurascope/aurascope/aurascope_nrf5340_shared.dtsi:65 */
		gpio-map-pass-thru = < 0x0 0x3f >;         /* in nrf/boards/aurascope/aurascope/aurascope_nrf5340_shared.dtsi:66 */
		gpio-map = < 0x0 0x0 &gpio0 0x4 0x0 >,
		           < 0x1 0x0 &gpio0 0x5 0x0 >,
		           < 0x2 0x0 &gpio0 0x6 0x0 >,
		           < 0x3 0x0 &gpio0 0x7 0x0 >,
		           < 0x4 0x0 &gpio0 0x19 0x0 >,
		           < 0x5 0x0 &gpio0 0x1a 0x0 >,
		           < 0x6 0x0 &gpio1 0x0 0x0 >,
		           < 0x7 0x0 &gpio1 0x1 0x0 >,
		           < 0x8 0x0 &gpio1 0x4 0x0 >,
		           < 0x9 0x0 &gpio1 0x5 0x0 >,
		           < 0xa 0x0 &gpio1 0x6 0x0 >,
		           < 0xb 0x0 &gpio1 0x7 0x0 >,
		           < 0xc 0x0 &gpio1 0x8 0x0 >,
		           < 0xd 0x0 &gpio1 0x9 0x0 >,
		           < 0xe 0x0 &gpio1 0xa 0x0 >,
		           < 0xf 0x0 &gpio1 0xb 0x0 >,
		           < 0x10 0x0 &gpio1 0xc 0x0 >,
		           < 0x11 0x0 &gpio1 0xd 0x0 >,
		           < 0x12 0x0 &gpio1 0xe 0x0 >,
		           < 0x13 0x0 &gpio1 0xf 0x0 >,
		           < 0x14 0x0 &gpio1 0x2 0x0 >,
		           < 0x15 0x0 &gpio1 0x3 0x0 >;    /* in nrf/boards/aurascope/aurascope/aurascope_nrf5340_shared.dtsi:67 */
		phandle = < 0x4 >;                         /* in nrf/boards/aurascope/aurascope/aurascope_nrf5340_cpunet.dts:48 */
	};
};
